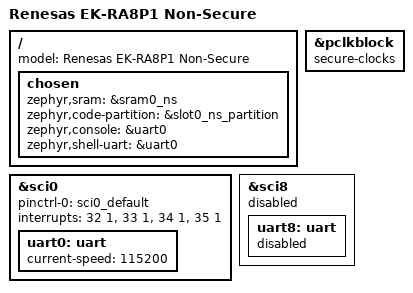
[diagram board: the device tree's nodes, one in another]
/*
 * Copyright (c) 2026 Renesas Electronics Corporation
 *
 * SPDX-License-Identifier: Apache-2.0
 */

/dts-v1/;

#include <renesas/ra/ra8/r7ka8p1kflcac_cm85_ns.dtsi>
#include "ek_ra8p1_r7ka8p1kflcac_cm85_common.dtsi"
#include "ek_ra8p1_r7ka8p1kflcac_ns_partition.dtsi"

/ {
	model = "Renesas EK-RA8P1 Non-Secure";

	chosen {
		zephyr,sram = &sram0_ns;
		zephyr,code-partition = &slot0_ns_partition;
		zephyr,console = &uart0;
		zephyr,shell-uart = &uart0;
	};
};

/* CGC is configured by the TF-M secure image */
&pclkblock {
	secure-clocks;
};

&sci0 {
	pinctrl-0 = <&sci0_default>;
	pinctrl-names = "default";
	interrupts = <32 1>, <33 1>, <34 1>, <35 1>;
	interrupt-names = "rxi", "txi", "tei", "eri";
	status = "okay";

	uart0: uart {
		current-speed = <115200>;
		status = "okay";
	};
};

&sci8 {
	status = "disabled";

	uart8: uart {
		/* SCI8 UART used for TF-M Secure app */
		status = "disabled";
	};
};
